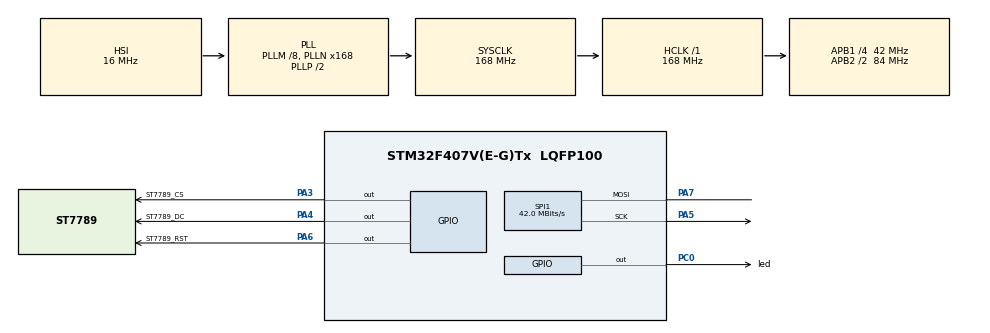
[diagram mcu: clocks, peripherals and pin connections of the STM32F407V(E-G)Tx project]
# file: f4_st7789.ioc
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Dma.Request0=SPI1_TX
Dma.SPI1_TX.0.Direction=DMA_MEMORY_TO_PERIPH
Dma.SPI1_TX.0.FIFOMode=DMA_FIFOMODE_ENABLE
Dma.SPI1_TX.0.FIFOThreshold=DMA_FIFO_THRESHOLD_FULL
Dma.SPI1_TX.0.Instance=DMA2_Stream3
Dma.SPI1_TX.0.MemBurst=DMA_MBURST_SINGLE
Dma.SPI1_TX.0.MemDataAlignment=DMA_MDATAALIGN_BYTE
Dma.SPI1_TX.0.MemInc=DMA_MINC_ENABLE
Dma.SPI1_TX.0.Mode=DMA_NORMAL
Dma.SPI1_TX.0.PeriphBurst=DMA_PBURST_SINGLE
Dma.SPI1_TX.0.PeriphDataAlignment=DMA_PDATAALIGN_BYTE
Dma.SPI1_TX.0.PeriphInc=DMA_PINC_DISABLE
Dma.SPI1_TX.0.Priority=DMA_PRIORITY_LOW
Mcu.Family=STM32F4
Mcu.Name=STM32F407V(E-G)Tx
Mcu.Package=LQFP100
NVIC.DMA2_Stream3_IRQn=true\:0\:0\:false\:false\:true\:false\:true\:true
NVIC.PriorityGroup=NVIC_PRIORITYGROUP_4
PA13.Mode=Serial_Wire
PA13.Signal=SYS_JTMS-SWDIO
PA14.Mode=Serial_Wire
PA14.Signal=SYS_JTCK-SWCLK
PA3.GPIO_Label=ST7789_CS
PA3.GPIO_PuPd=GPIO_PULLUP
PA3.GPIO_Speed=GPIO_SPEED_FREQ_VERY_HIGH
PA3.PinState=GPIO_PIN_SET
PA3.Signal=GPIO_Output
PA4.GPIO_Label=ST7789_DC
PA4.GPIO_Speed=GPIO_SPEED_FREQ_VERY_HIGH
PA4.Signal=GPIO_Output
PA5.Mode=Simplex_Bidirectional_Master
PA5.Signal=SPI1_SCK
PA6.GPIO_Label=ST7789_RST
PA6.GPIO_PuPd=GPIO_PULLUP
PA6.GPIO_Speed=GPIO_SPEED_FREQ_VERY_HIGH
PA6.PinState=GPIO_PIN_SET
PA6.Signal=GPIO_Output
PA7.Mode=Simplex_Bidirectional_Master
PA7.Signal=SPI1_MOSI
PC0.GPIO_Label=led
PC0.GPIO_Speed=GPIO_SPEED_FREQ_VERY_HIGH
PC0.Signal=GPIO_Output
PH0-OSC_IN.Mode=HSE-External-Oscillator
PH0-OSC_IN.Signal=RCC_OSC_IN
PH1-OSC_OUT.Mode=HSE-External-Oscillator
PH1-OSC_OUT.Signal=RCC_OSC_OUT
ProjectManager.HeapSize=0x200
ProjectManager.StackSize=0x400
ProjectManager.TargetToolchain=CMake
RCC.48MHZClocksFreq_Value=84000000
RCC.AHBFreq_Value=168000000
RCC.APB1CLKDivider=RCC_HCLK_DIV4
RCC.APB1Freq_Value=42000000
RCC.APB1TimFreq_Value=84000000
RCC.APB2CLKDivider=RCC_HCLK_DIV2
RCC.APB2Freq_Value=84000000
RCC.APB2TimFreq_Value=168000000
RCC.CortexFreq_Value=168000000
RCC.HCLKFreq_Value=168000000
RCC.HSE_VALUE=8000000
RCC.HSI_VALUE=16000000
RCC.LSE_VALUE=32768
RCC.PLLM=8
RCC.PLLN=168
RCC.SYSCLKFreq_VALUE=168000000
RCC.SYSCLKSource=RCC_SYSCLKSOURCE_PLLCLK
RCC.VCOOutputFreq_Value=336000000
SPI1.BaudRatePrescaler=SPI_BAUDRATEPRESCALER_2
SPI1.CLKPolarity=SPI_POLARITY_LOW
SPI1.CalculateBaudRate=42.0 MBits/s
SPI1.Direction=SPI_DIRECTION_1LINE
SPI1.Mode=SPI_MODE_MASTER
SPI1.VirtualType=VM_MASTER
board=custom

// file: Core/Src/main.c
/* USER CODE BEGIN Header */
/**
 ******************************************************************************
 * @file           : main.c
 * @brief          : Main program body
 ******************************************************************************
 * @attention
 *
 * Copyright (c) 2025 STMicroelectronics.
 * All rights reserved.
 *
 * This software is licensed under terms that can be found in the LICENSE file
 * in the root directory of this software component.
 * If no LICENSE file comes with this software, it is provided AS-IS.
 *
 ******************************************************************************
 */
/* USER CODE END Header */
#include "main.h"
#include "dma.h"
#include "gpio.h"
#include "spi.h"

/* USER CODE BEGIN Includes */
#include "st7789.h"
#include "stm32f4xx_hal.h"
#include "stm32f4xx_hal_gpio.h"
/* USER CODE END Includes */

void SystemClock_Config(void);

int main(void) {

  /* MCU Configuration--------------------------------------------------------*/

  /* Reset of all peripherals, Initializes the Flash interface and the Systick.
   */
  HAL_Init();

  /* Configure the system clock */
  SystemClock_Config();

  /* Initialize all configured peripherals */
  MX_GPIO_Init();
  MX_DMA_Init();
  MX_SPI1_Init();
  /* USER CODE BEGIN 2 */
  // HAL_Delay(4000);
  ST7789_Init();
  /* USER CODE END 2 */

  /* Infinite loop */
  /* USER CODE BEGIN WHILE */
  while (1) {
    ST7789_Test();
    HAL_GPIO_TogglePin(led_GPIO_Port, led_Pin);
    HAL_Delay(200);
    /* USER CODE END WHILE */

  }
}

void SystemClock_Config(void) {
  RCC_OscInitTypeDef RCC_OscInitStruct = {0};
  RCC_ClkInitTypeDef RCC_ClkInitStruct = {0};

  /** Configure the main internal regulator output voltage
   */
  __HAL_RCC_PWR_CLK_ENABLE();
  __HAL_PWR_VOLTAGESCALING_CONFIG(PWR_REGULATOR_VOLTAGE_SCALE1);

  /** Initializes the RCC Oscillators according to the specified parameters
   * in the RCC_OscInitTypeDef structure.
   */
  RCC_OscInitStruct.OscillatorType = RCC_OSCILLATORTYPE_HSI;
  RCC_OscInitStruct.HSIState = RCC_HSI_ON;
  RCC_OscInitStruct.HSICalibrationValue = RCC_HSICALIBRATION_DEFAULT;
  RCC_OscInitStruct.PLL.PLLState = RCC_PLL_ON;
  RCC_OscInitStruct.PLL.PLLSource = RCC_PLLSOURCE_HSI;
  RCC_OscInitStruct.PLL.PLLM = 8;
  RCC_OscInitStruct.PLL.PLLN = 168;
  RCC_OscInitStruct.PLL.PLLP = RCC_PLLP_DIV2;
  RCC_OscInitStruct.PLL.PLLQ = 4;
  if (HAL_RCC_OscConfig(&RCC_OscInitStruct) != HAL_OK) {
    Error_Handler();
  }

  /** Initializes the CPU, AHB and APB buses clocks
   */
  RCC_ClkInitStruct.ClockType = RCC_CLOCKTYPE_HCLK | RCC_CLOCKTYPE_SYSCLK |
                                RCC_CLOCKTYPE_PCLK1 | RCC_CLOCKTYPE_PCLK2;
  RCC_ClkInitStruct.SYSCLKSource = RCC_SYSCLKSOURCE_PLLCLK;
  RCC_ClkInitStruct.AHBCLKDivider = RCC_SYSCLK_DIV1;
  RCC_ClkInitStruct.APB1CLKDivider = RCC_HCLK_DIV4;
  RCC_ClkInitStruct.APB2CLKDivider = RCC_HCLK_DIV2;

  if (HAL_RCC_ClockConfig(&RCC_ClkInitStruct, FLASH_LATENCY_5) != HAL_OK) {
    Error_Handler();
  }
}

void Error_Handler(void) {
  __disable_irq();
  while (1) {
  }
}

#ifdef USE_FULL_ASSERT
/**
 * @brief  Reports the name of the source file and the source line number
 *         where the assert_param error has occurred.
 * @param  file: pointer to the source file name
 * @param  line: assert_param error line source number
 * @retval None
 */
void assert_failed(uint8_t *file, uint32_t line) {
  /* USER CODE BEGIN 6 */
  /* User can add his own implementation to report the file name and line
     number, ex: printf("Wrong parameters value: file %s on line %d\r\n", file,
     line) */
  /* USER CODE END 6 */
}
#endif /* USE_FULL_ASSERT */
